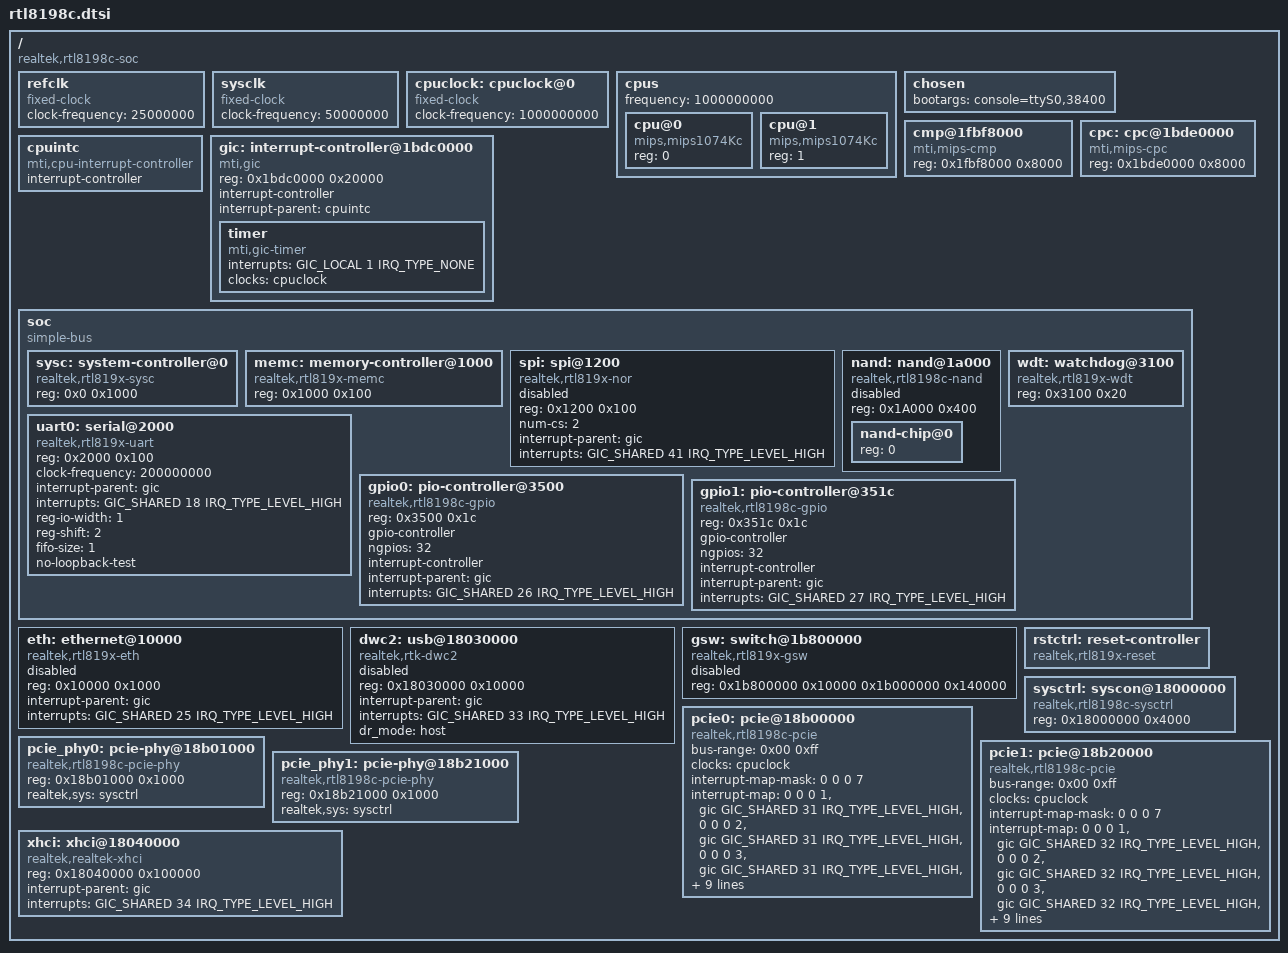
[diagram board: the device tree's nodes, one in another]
// SPDX-License-Identifier: GPL-2.0-or-later OR MIT

#include <dt-bindings/interrupt-controller/mips-gic.h>


/dts-v1/;

/ {
	#address-cells = <1>;
	#size-cells = <1>;

	compatible = "realtek,rtl8198c-soc";

	refclk: refclk {
		#clock-cells = <0>;
		compatible = "fixed-clock";
		clock-frequency = <25000000>;
	};

	sysclk: sysclk {
		#clock-cells = <0>;
		compatible = "fixed-clock";
		clock-frequency = <50000000>;
	};

	cpuclock: cpuclock@0 {
		#clock-cells = <0>;
		compatible = "fixed-clock";
		clock-frequency = <1000000000>;
	};

	cpus {
		#address-cells = <1>;
		#size-cells = <0>;
		frequency = <1000000000>;

		cpu@0 {
			compatible = "mips,mips1074Kc";
			reg = <0>;
		};

		cpu@1 {
			compatible = "mips,mips1074Kc";
			reg = <1>;
		};
	};

	chosen {
		bootargs = "console=ttyS0,38400";
	};

	cmp@1fbf8000 {
		compatible = "mti,mips-cmp";
		reg = <0x1fbf8000 0x8000>;
	};

	cpc: cpc@1bde0000 {
		compatible = "mti,mips-cpc";
		reg = <0x1bde0000 0x8000>;
	};

	cpuintc: cpuintc {
		compatible = "mti,cpu-interrupt-controller";
		#address-cells = <0>;
		#interrupt-cells = <1>;
		interrupt-controller;
	};

	gic: interrupt-controller@1bdc0000 {
		compatible = "mti,gic";
		reg = <0x1bdc0000 0x20000>;

		interrupt-controller;
		#interrupt-cells = <3>;

		/*
		 * Declare the interrupt-parent even though the mti,gic
		 * binding doesn't require it, such that the kernel can
		 * figure out that cpu_intc is the root interrupt
		 * controller & should be probed first.
		 */
		interrupt-parent = <&cpuintc>;

		timer {
			compatible = "mti,gic-timer";
			interrupts = <GIC_LOCAL 1 IRQ_TYPE_NONE>;
			clocks = <&cpuclock>;
		};
	};

	soc: soc {
		compatible = "simple-bus";
		#address-cells = <1>;
		#size-cells = <1>;
		ranges = <0x0 0x18000000 0x40000>;

		sysc: system-controller@0 {
			compatible = "realtek,rtl819x-sysc";
			reg = <0x0 0x1000>;
		};

		memc: memory-controller@1000 {
			compatible = "realtek,rtl819x-memc";
			reg = <0x1000 0x100>;
		};

		spi: spi@1200 {
			compatible = "realtek,rtl819x-nor";
			reg = <0x1200 0x100>;
			#address-cells = <1>;
			#size-cells = <0>;
			num-cs = <2>;
			interrupt-parent = <&gic>;
			interrupts = <GIC_SHARED 41 IRQ_TYPE_LEVEL_HIGH>;
			status = "disabled";
		};

		nand: nand@1a000 {
			compatible = "realtek,rtl8198c-nand";
			reg = <0x1A000 0x400>;
			#address-cells = <1>;
			#size-cells = <1>;
			status = "disabled";

			nand-chip@0 {
				reg = <0>;
			};
		};

		uart0: serial@2000 {
			compatible = "realtek,rtl819x-uart", "ns16550a";
			reg = <0x2000 0x100>;

			clock-frequency = <200000000>;

			interrupt-parent = <&gic>;
			#interrupt-cells = <3>;
			interrupts = <GIC_SHARED 18 IRQ_TYPE_LEVEL_HIGH>;

			reg-io-width = <1>;
			reg-shift = <2>;
			fifo-size = <1>;
			no-loopback-test;
		};

		wdt: watchdog@3100 {
			compatible = "realtek,rtl819x-wdt";
			reg = <0x3100 0x20>;
		};

		gpio0: pio-controller@3500 {
			compatible = "realtek,rtl8198c-gpio", "realtek,otto-gpio";
			reg = <0x3500 0x1c>;

			gpio-controller;
			#gpio-cells = <2>;
			ngpios = <32>;

			interrupt-controller;
			#interrupt-cells = <2>;
			interrupt-parent = <&gic>;
			interrupts = <GIC_SHARED 26 IRQ_TYPE_LEVEL_HIGH>;
		};

		gpio1: pio-controller@351c {
			compatible = "realtek,rtl8198c-gpio", "realtek,otto-gpio";
			reg = <0x351c 0x1c>;

			gpio-controller;
			#gpio-cells = <2>;
			ngpios = <32>;

			interrupt-controller;
			#interrupt-cells = <2>;
			interrupt-parent = <&gic>;
			interrupts = <GIC_SHARED 27 IRQ_TYPE_LEVEL_HIGH>;
		};
	};

	eth: ethernet@10000 {
		compatible = "realtek,rtl819x-eth";
		/* CPU interface at 0x18010000; the switch core itself
		 * (0x18040000) is outside this bus window and the driver
		 * reaches it through KSEG1 like the rest of the switch. */
		reg = <0x10000 0x1000>;
		interrupt-parent = <&gic>;
		interrupts = <GIC_SHARED 25 IRQ_TYPE_LEVEL_HIGH>;
		status = "disabled";
	};

	dwc2: usb@18030000 {
		compatible = "realtek,rtk-dwc2";
		reg = <0x18030000 0x10000>;
		interrupt-parent = <&gic>;
		interrupts = <GIC_SHARED 33 IRQ_TYPE_LEVEL_HIGH>;
		dr_mode = "host";
		status = "disabled";
	};

	gsw: switch@1b800000 {
		compatible = "realtek,rtl819x-gsw";
		reg = <0x1b800000 0x10000
		       0x1b000000 0x140000>;
		status = "disabled";
	};

	rstctrl: reset-controller {
		compatible = "realtek,rtl819x-reset";
		#reset-cells = <1>;
	};

	sysctrl: syscon@18000000 {
		compatible = "realtek,rtl8198c-sysctrl", "syscon";
		reg = <0x18000000 0x4000>;
	};

	pcie0: pcie@18b00000 {
		compatible = "realtek,rtl8198c-pcie";
		#address-cells = <3>;
		#size-cells = <2>;
		bus-range = <0x00 0xff>;
		clocks = <&cpuclock>;
		device_type = "pci";
		#interrupt-cells = <1>;
		interrupt-map-mask = <0 0 0 7>;
		interrupt-map = <0 0 0 1 &gic GIC_SHARED 31 IRQ_TYPE_LEVEL_HIGH>,
				<0 0 0 2 &gic GIC_SHARED 31 IRQ_TYPE_LEVEL_HIGH>,
				<0 0 0 3 &gic GIC_SHARED 31 IRQ_TYPE_LEVEL_HIGH>,
				<0 0 0 4 &gic GIC_SHARED 31 IRQ_TYPE_LEVEL_HIGH>;
		interrupt-parent = <&gic>;
		interrupts = <GIC_SHARED 31 IRQ_TYPE_LEVEL_HIGH>;
		ranges = <0x02000000 0 0x19000000 0x19000000 0 0x01000000>; /* identity mapped pci memory */
		reg = <0x18b00000 0x1000>,	/* host config */
		      <0x18b10000 0x2000>;	/* device config, one window per function */
		reg-names = "hostcfg", "devcfg";
		linux,pci-domain = <0>;
		phys = <&pcie_phy0>;
		realtek,sys = <&sysctrl>;
		slot-num = <0>;
	};

	pcie_phy0: pcie-phy@18b01000 {
		compatible = "realtek,rtl8198c-pcie-phy";
		reg = <0x18b01000 0x1000>;
		realtek,sys = <&sysctrl>;
		#phy-cells = <0>;
	};

	pcie1: pcie@18b20000 {
		compatible = "realtek,rtl8198c-pcie";
		#address-cells = <3>;
		#size-cells = <2>;
		bus-range = <0x00 0xff>;
		clocks = <&cpuclock>;
		device_type = "pci";
		#interrupt-cells = <1>;
		interrupt-map-mask = <0 0 0 7>;
		interrupt-map = <0 0 0 1 &gic GIC_SHARED 32 IRQ_TYPE_LEVEL_HIGH>,
				<0 0 0 2 &gic GIC_SHARED 32 IRQ_TYPE_LEVEL_HIGH>,
				<0 0 0 3 &gic GIC_SHARED 32 IRQ_TYPE_LEVEL_HIGH>,
				<0 0 0 4 &gic GIC_SHARED 32 IRQ_TYPE_LEVEL_HIGH>;
		interrupt-parent = <&gic>;
		interrupts = <GIC_SHARED 32 IRQ_TYPE_LEVEL_HIGH>;
		ranges = <0x02000000 0 0x1a000000 0x1a000000 0 0x01000000>; /* identity mapped pci memory */
		reg = <0x18b20000 0x1000>,	/* host config */
		      <0x18b30000 0x2000>;	/* device config, one window per function */
		reg-names = "hostcfg", "devcfg";
		linux,pci-domain = <1>;
		phys = <&pcie_phy1>;
		realtek,sys = <&sysctrl>;
		slot-num = <1>;
	};

	pcie_phy1: pcie-phy@18b21000 {
		compatible = "realtek,rtl8198c-pcie-phy";
		reg = <0x18b21000 0x1000>;
		realtek,sys = <&sysctrl>;
		#phy-cells = <0>;
	};

	xhci: xhci@18040000 {
		compatible = "realtek,realtek-xhci";
		reg = <0x18040000 0x100000>;
		interrupt-parent = <&gic>;
		interrupts = <GIC_SHARED 34 IRQ_TYPE_LEVEL_HIGH>;
	};
};
